# N575F145_v1 register map
File version: 1.0
Registers are 32-bit, read-write, reset 0x0 unless marked. A register's access mark holds for its fields unless they carry their own. Offsets are from the block's base; [hi:lo] are bit positions; 'fields as' and 'values as' point back to an identical list; <NAME> marks a mode.

## SPI0 — SPI0 Register Map
Base 0x40030000
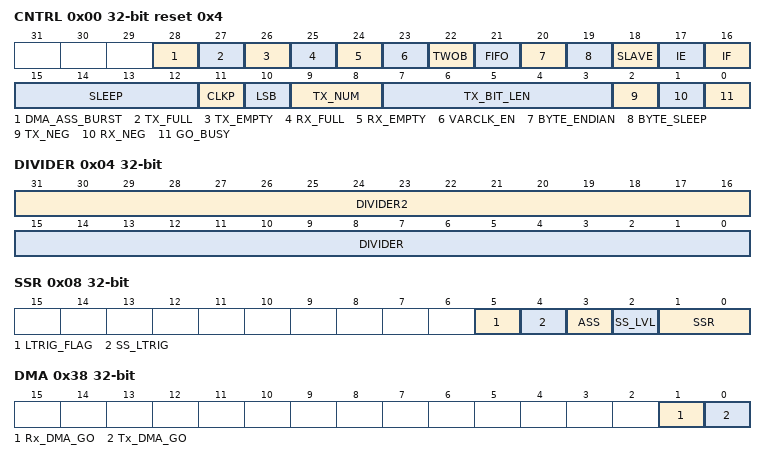
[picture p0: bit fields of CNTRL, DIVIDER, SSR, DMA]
0x00 CNTRL reset 0x4 — Control and Status Register
  [28] DMA_ASS_BURST — Enable DMA Automatic SS function. When enabled, interface will automatically generate a SS signal for an entire PDMA access transaction.
  [27] TX_FULL — Transmit FIFO Full Status
    0=The transmit data FIFO is not full; 1=The transmit data FIFO is full
  [26] TX_EMPTY — Transmit FIFO Empty Status
    0=The transmit data FIFO is not empty; 1=The transmit data FIFO is empty
  [25] RX_FULL — Receive FIFO Full Status
    0=The receive data FIFO is not full; 1=The receive data FIFO is full
  [24] RX_EMPTY — Receive FIFO Empty Status
    0=The receive data FIFO is not empty; 1=The receive data FIFO is empty
  [23] VARCLK_EN — Variable Clock Enable (Master Only). Note that when enabled, the setting of TX_BIT_LEN must be programmed as 0x10 (16 bits mode)
    0=The serial clock output frequency is fixed and determined only by the value of DIVIDER; 1=SCLK output frequency is variable. The output frequency is determined by the value of VARCLK, DIVIDER, and DIVIDER2
  [22] TWOB — Two Bits Transfer Mode. Note that when enabled in master mode, MOSI0 data comes from TX[0] and MOSI1 data from TX[1]. Likewise RX[0] receives bit stream from MISO0 and RX[1] from MISO1. Note that when enabled, the setting of TX_NUM must be programmed as 0x00
    0=Disable two-bit transfer mode; 1=Enable two-bit transfer mode
  [21] FIFO — FIFO Mode
    0=No FIFO present on transmit and receive buffer; 1=Enable FIFO on transmit and receive buffer
  [20] BYTE_ENDIAN — Byte Endian Reorder Function. This function changes the order of bytes sent/received to be least significant physical byte first.
  [19] BYTE_SLEEP — Insert Sleep Interval Between Bytes. This function is only valid for 32bit transfers (TX_BIT_LEN = 0). If set then a pause of (SLEEP+2) SCLK cycles is inserted between each byte transmitted.
  [18] SLAVE — Master Slave Mode Control
    0=Master mode; 1=Slave mode
  [17] IE — Interrupt Enable
    0=Disable SPI Interrupt; 1=Enable SPI Interrupt to CPU
  [16] IF — Interrupt Flag. NOTE: This bit is cleared by writing 1 to itself.
    0=Indicates the transfer is not finished yet; 1=Indicates that the transfer is complete. Interrupt is generated to CPU if enabled
  [15:12] SLEEP — Suspend Interval (Master Only). These four bits provide configurable suspend interval between two successive transmit/receive transactions in a transfer. The suspend interval is from the last falling clock edge of the current transaction to the first rising clock edge of the successive transaction if CLKP = 0. If CLKP = 1, the interval is from the rising clock edge to the falling clock edge. The default value is 0x0. When TX_NUM = 00b, setting this field has no effect on transfer except as determined by REORDER[0] setting. The suspend interval is determined according to the following equation: (SLEEP[3:0] + 2) * period of SCLK
  [11] CLKP — Clock Polarity
    0=SCLK idle low; 1=SCLK idle high
  [10] LSB — LSB First
    0=The MSB is transmitted/received first (which bit in SPI_TX[0]/[1] and SPI_RX[0]/[1] register that is depends on the TX_BIT_LEN field); 1=The LSB is sent first on the line (bit 0 of SPI_TX[0]/[1]), and the first bit received from the line will be put in the LSB position in the Rx register (bit 0 of SPI_RX[0]/[1])
  [9:8] TX_NUM — Transmit/Receive Word Numbers. This field specifies how many transmit/receive word numbers should be executed in one transfer.
    0=Only one transmit/receive word will be executed in one transfer; 1=Two successive transmit/receive word will be executed in one transfer
  [7:3] TX_BIT_LEN — Transmit Bit Length. This field specifies how many bits are transmitted in one transmit/receive. Up to 32 bits can be transmitted. TX_BIT_LEN = 0x01 --- 1 bit. TX_BIT_LEN = 0x02 --- 2 bits ---- TX_BIT_LEN = 0x1f --- 31 bits. TX_BIT_LEN = 0x00 --- 32 bits
  [2] TX_NEG — Transmit At Negative Edge
    0=The transmitted data output signal is changed at the rising edge of SCLK; 1=The transmitted data output signal is changed at the falling edge of SCLK
  [1] RX_NEG — Receive At Negative Edge
    0=The received data input signal is latched at the rising edge of SCLK; 1=The received data input signal is latched at the falling edge of SCLK
  [0] GO_BUSY — Go and Busy Status. NOTE: All registers should be set before writing 1 to this GO_BUSY bit. When a transfer is in progress, writing to any register of the SPI master/slave core has no effect.
    0=Writing 0 to this bit has no effect; 1=Writing 1 to this bit starts the transfer. This bit remains set during the transfer and is automatically cleared after transfer finished
0x04 DIVIDER — Clock Divider Register (Master Only)
  [31:16] DIVIDER2 — Clock Divider 2 Register (master only). The value in this field is the 2nd frequency divider of the system clock, PCLK, to generate the serial clock on the output SCLK. The desired frequency is obtained according to the following equation: Fsclk = Fpclk / ((DIVIDER2+1) * 2)
  [15:0] DIVIDER — Clock Divider Register (master only). The value in this field is the frequency division of the system clock, PCLK, to generate the serial clock on the output SCLK. The desired frequency is obtained according to the following equation: Fsclk = Fpclk / ((DIVIDER+1) * 2). In slave mode, the period of SPI clock driven by a master shall satisfy. Fsclk < = (Fpclk / 5). In other words, the maximum frequency of SCLK clock is one fifth of the SPI peripheral clock.
0x08 SSR — Slave Select Register
  [5] LTRIG_FLAG — Level Trigger Flag. When the SS_LTRIG bit is set in slave mode, this bit can be read to indicate the received bit number is met the requirement or not. Note: This bit is READ only
    0=One of the received number and the received bit length doesn't meet the requirement in one transfer; 1=The received number and received bits met the requirement which defines in Tx_NUM and Tx_BIT_LEN among one transfer
  [4] SS_LTRIG — Slave Select Level Trigger (Slave only)
    0=The input slave select signal is edge-trigger. This is the default value; 1=The slave select signal will be level-trigger. It depends on SS_LVL to decide the signal is active low or active high
  [3] ASS — Automatic Slave Select (Master only)
    0=If this bit is cleared, slave select signals are asserted and de-asserted by setting and clearing related bits in SSR[1:0] register; 1=If this bit is set, SPISSx0/1 signals are generated automatically. It means that device/slave select signal, which is set in SSR[1:0] register is asserted by the SPI controller when transmit/receive is started by setting GO_BUSY, and is de-asserted after each transmit/receive is finished
  [2] SS_LVL — Slave Select Active Level. It defines the active level of device/slave select signal (SPISSx0/1).
    0=The slave select signal SPISSx0/1 is active at low-level/falling-edge; 1=The slave select signal SPISSx0/1 is active at high-level/rising-edge
  [1:0] SSR — Slave Select Register (Master only). If ASS bit is cleared, writing 1 to any bit location of this field sets the proper SPISSx0/1 line to an active state and writing 0 sets the line back to inactive state. If ASS bit is set, writing 1 to any bit location of this field will select appropriate SPISSx0/1 line to be automatically driven to active state for the duration of the transmit/receive, and will be driven to inactive state for the rest of the time. (The active level of SPISSx0/1 is specified in SS_LVL). Note: SPISSx0 is always defined as device/slave select input signal in slave mode.
0x10 RX0 ro — Data Receive Register 0
  [31:0] RX — Data Receive Register. The Data Receive Registers hold the value of received data of the last executed transfer. Valid bits depend on the transmit bit length field in the SPI_CNTRL register. For example, if Tx_BIT_LEN is set to 0x08 and Tx_NUM is set to 0x0, bit Rx0[7:0] holds the received data. NOTE: The Data Receive Registers are read only registers.
0x14 RX1 ro — Data Receive Register 0
  fields as RX0
0x20 TX0 wo — Data Transmit Register 0
  [31:0] Tx — Data Transmit Register. The Data Transmit Registers hold the data to be transmitted in the next transfer. Valid bits depend on the transmit bit length field in the CNTRL register. For example, if Tx_BIT_LEN is set to 0x08 and the Tx_NUM is set to 0x0, the bit Tx0[7:0] will be transmitted in next transfer. If Tx_BIT_LEN is set to 0x00 and Tx_NUM is set to 0x1, the core will perform two 32-bit transmit/receive successive using the same setting (the order is Tx0[31:0], Tx1[31:0]).
0x24 TX1 wo — Data Transmit Register 0
  fields as TX0
0x34 VARCLK reset 0x7FFF87 — Variable Clock Pattern Register
  [31:0] VARCLK — Variable Clock Pattern. The value in this field is the frequency pattern of the SPI clock. If the bit field of VARCLK is '0', the output frequency of SCLK is given by the value of DIVIDER. If the bit field of VARCLK is '1', the output frequency of SCLK is given by the value of DIVIDER2. Refer to register DIVIDER. Refer to Variable Serial Clock Frequency paragraph for detailed description.
0x38 DMA — SPI DMA Control Register
  [1] Rx_DMA_GO — Receive DMA Start. Set this bit to 1 will start the receive DMA process. SPI module will issue request to DMA module automatically.
  [0] Tx_DMA_GO — Transmit DMA Start. Set this bit to 1 will start the transmit DMA process. SPI module will issue request to DMA module automatically. If using DMA mode to transfer data, remember not to set GO_BUSY bit of SPI_CNTRL register. The DMA controller inside SPI module will set it automatically whenever necessary.
